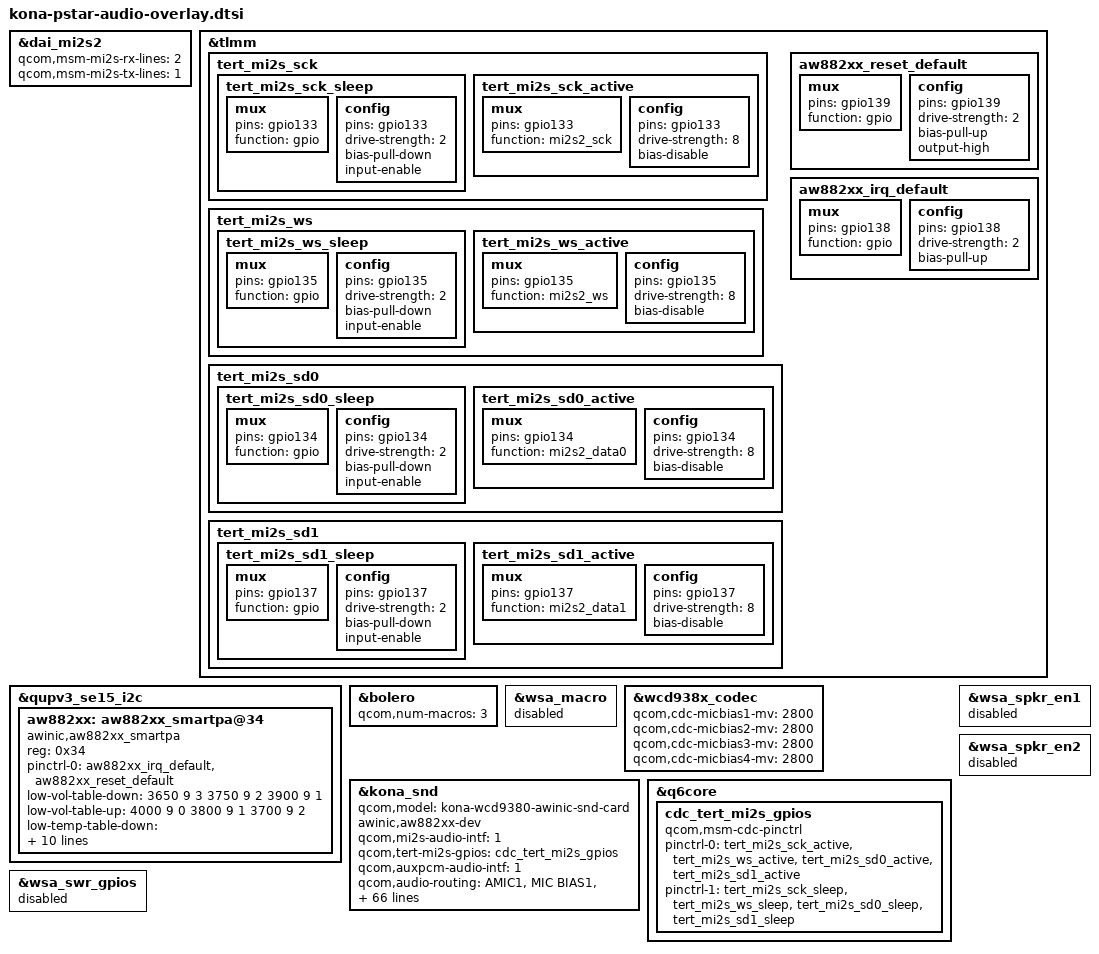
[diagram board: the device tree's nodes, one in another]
#include "kona-audio-overlay.dtsi"

&dai_mi2s2 {
	qcom,msm-mi2s-rx-lines = <2>;
	qcom,msm-mi2s-tx-lines = <1>;
};

&tlmm {

	tert_mi2s_sck {
		tert_mi2s_sck_sleep: tert_mi2s_sck_sleep {
			mux {
				pins = "gpio133";
				function = "gpio";
			};
			config {
				pins = "gpio133";
				drive-strength = <2>; /* 2 mA */
				bias-pull-down; /* PULL DOWN */
				input-enable;
			};
		};

		tert_mi2s_sck_active: tert_mi2s_sck_active {
			mux {
				pins = "gpio133";
				function = "mi2s2_sck";
			};
			config {
				pins = "gpio133";
				drive-strength = <8>; /* 8 mA */
				bias-disable; /* NO PULL */
			};
		};
	};
	tert_mi2s_ws {
		tert_mi2s_ws_sleep: tert_mi2s_ws_sleep {
			mux {
				pins = "gpio135";
				function = "gpio";
			};
			config {
				pins = "gpio135";
				drive-strength = <2>; /* 2 mA */
				bias-pull-down; /* PULL DOWN */
				input-enable;
			};
		};
		tert_mi2s_ws_active: tert_mi2s_ws_active {
			mux {
				pins = "gpio135";
				function = "mi2s2_ws";
			};
			config {
				pins = "gpio135";
				drive-strength = <8>; /* 8 mA */
				bias-disable; /* NO PULL */
			};
		};
	};
	tert_mi2s_sd0 {
		tert_mi2s_sd0_sleep: tert_mi2s_sd0_sleep {
			mux {
				pins = "gpio134";
				function = "gpio";
			};
			config {
				pins = "gpio134";
				drive-strength = <2>; /* 2 mA */
				bias-pull-down; /* PULL DOWN */
				input-enable;
			};
		};
		tert_mi2s_sd0_active: tert_mi2s_sd0_active {
			mux {
				pins = "gpio134";
				function = "mi2s2_data0";
			};
			config {
				pins = "gpio134";
				drive-strength = <8>; /* 8 mA */
				bias-disable; /* NO PULL */
			};
		};
	};
	tert_mi2s_sd1 {
		tert_mi2s_sd1_sleep: tert_mi2s_sd1_sleep {
			mux {
				pins = "gpio137";
				function = "gpio";
			};
			config {
				pins = "gpio137";
				drive-strength = <2>; /* 2 mA */
				bias-pull-down; /* PULL DOWN */
				input-enable;
			};
		};
		tert_mi2s_sd1_active: tert_mi2s_sd1_active {
			mux {
				pins = "gpio137";
				function = "mi2s2_data1";
			};
			config {
				pins = "gpio137";
				drive-strength = <8>; /* 8 mA */
				bias-disable; /* NO PULL */
			};
		};
	};

	aw882xx_reset_default: aw882xx_reset_default {
		mux {
			pins = "gpio139";
			function = "gpio";
		};
		config {
			pins = "gpio139";
			drive-strength = <2>; /* 2 MA */
			bias-pull-up;
			output-high;
		};
	};

	aw882xx_irq_default: aw882xx_irq_default {
		mux {
			pins = "gpio138";
			function = "gpio";
		};
		config {
			pins = "gpio138";
			drive-strength = <2>; /* 2 MA */
			bias-pull-up;
		};
	};
};

&qupv3_se15_i2c {
        status = "ok";

        aw882xx: aw882xx_smartpa@34 {
                compatible = "awinic,aw882xx_smartpa";
                reg = <0x34>;

                pinctrl-names = "default";
                pinctrl-0 = <&aw882xx_irq_default>, <&aw882xx_reset_default>;

                low-vol-table-down = <3650 9 3 3750 9 2 3900 9 1>;
                low-vol-table-up = <4000 9 0 3800 9 1 3700 9 2>;

                low-temp-table-down = <0xFFFFFFFB 0x4 0x10 0xFFBEAE7E 0x0 0x5 0x9 0xFFD80505 0x5 0x6 0x6 0xFFED714D>;
                low-temp-table-up = <0x7 0x9 0x0 0x00000000 0x2 0x6 0x06 0xFFED714D 0xFFFFFFE 0x05 0x09 0xFFD80505>;

                afe-rx-portid = <0x1004>;
                afe-tx-portid = <0x1005>;

                reset-gpio = <&tlmm 139 0>;
                irq-gpio = <&tlmm 138 0x2008>;
                monitor-flag = <1>;
		fade-flag = <1>;
                monitor-timer-val = <3000>;
                status = "okay";
        };
};

&bolero {
	qcom,num-macros = <3>;
};

&wsa_macro {
	status = "disabled";
};

&wcd938x_codec {
	qcom,cdc-micbias1-mv = <2800>;
	qcom,cdc-micbias2-mv = <2800>;
	qcom,cdc-micbias3-mv = <2800>;
	qcom,cdc-micbias4-mv = <2800>;
};

&kona_snd {
        qcom,model = "kona-wcd9380-awinic-snd-card";
	awinic,aw882xx-dev;
        qcom,mi2s-audio-intf = <1>;
	qcom,tert-mi2s-gpios = <&cdc_tert_mi2s_gpios>;
        qcom,auxpcm-audio-intf = <1>;
	qcom,audio-routing =
		"AMIC1", "MIC BIAS1",
		"MIC BIAS1", "Analog Mic1",
		"AMIC2", "MIC BIAS2",
		"MIC BIAS2", "Analog Mic2",
		"AMIC3", "MIC BIAS3",
		"MIC BIAS3", "Analog Mic3",
		"AMIC4", "MIC BIAS4",
		"MIC BIAS4", "Analog Mic4",
		"AMIC5", "MIC BIAS4",
		"MIC BIAS4", "Analog Mic5",
		"TX DMIC0", "MIC BIAS3",
		"MIC BIAS3", "Digital Mic0",
		"TX DMIC1", "MIC BIAS3",
		"MIC BIAS3", "Digital Mic1",
		"TX DMIC2", "MIC BIAS1",
		"MIC BIAS1", "Digital Mic2",
		"TX DMIC3", "MIC BIAS1",
		"MIC BIAS1", "Digital Mic3",
		"TX DMIC4", "MIC BIAS4",
		"MIC BIAS4", "Digital Mic4",
		"TX DMIC5", "MIC BIAS4",
		"MIC BIAS4", "Digital Mic5",
		"IN1_HPHL", "HPHL_OUT",
		"IN2_HPHR", "HPHR_OUT",
		"IN3_AUX", "AUX_OUT",
		"TX SWR_ADC0", "ADC1_OUTPUT",
		"TX SWR_ADC1", "ADC2_OUTPUT",
		"TX SWR_ADC2", "ADC3_OUTPUT",
		"TX SWR_ADC3", "ADC4_OUTPUT",
		"TX SWR_DMIC0", "DMIC1_OUTPUT",
		"TX SWR_DMIC1", "DMIC2_OUTPUT",
		"TX SWR_DMIC2", "DMIC3_OUTPUT",
		"TX SWR_DMIC3", "DMIC4_OUTPUT",
		"TX SWR_DMIC4", "DMIC5_OUTPUT",
		"TX SWR_DMIC5", "DMIC6_OUTPUT",
		"TX SWR_DMIC6", "DMIC7_OUTPUT",
		"TX SWR_DMIC7", "DMIC8_OUTPUT",
		"WSA SRC0_INP", "SRC0",
		"WSA_TX DEC0_INP", "TX DEC0 MUX",
		"WSA_TX DEC1_INP", "TX DEC1 MUX",
		"RX_TX DEC0_INP", "TX DEC0 MUX",
		"RX_TX DEC1_INP", "TX DEC1 MUX",
		"RX_TX DEC2_INP", "TX DEC2 MUX",
		"RX_TX DEC3_INP", "TX DEC3 MUX",
		"SpkrRight IN", "WSA_SPK2 OUT",
		"VA_AIF1 CAP", "VA_SWR_CLK",
		"VA_AIF2 CAP", "VA_SWR_CLK",
		"VA_AIF3 CAP", "VA_SWR_CLK",
		"VA MIC BIAS3", "Digital Mic0",
		"VA MIC BIAS3", "Digital Mic1",
		"VA MIC BIAS1", "Digital Mic2",
		"VA MIC BIAS1", "Digital Mic3",
		"VA MIC BIAS4", "Digital Mic4",
		"VA MIC BIAS4", "Digital Mic5",
		"VA DMIC0", "VA MIC BIAS3",
		"VA DMIC1", "VA MIC BIAS3",
		"VA DMIC2", "VA MIC BIAS1",
		"VA DMIC3", "VA MIC BIAS1",
		"VA DMIC4", "VA MIC BIAS4",
		"VA DMIC5", "VA MIC BIAS4",
		"VA SWR_ADC0", "VA_SWR_CLK",
		"VA SWR_ADC1", "VA_SWR_CLK",
		"VA SWR_ADC2", "VA_SWR_CLK",
		"VA SWR_ADC3", "VA_SWR_CLK",
		"VA SWR_MIC0", "VA_SWR_CLK",
		"VA SWR_MIC1", "VA_SWR_CLK",
		"VA SWR_MIC2", "VA_SWR_CLK",
		"VA SWR_MIC3", "VA_SWR_CLK",
		"VA SWR_MIC4", "VA_SWR_CLK",
		"VA SWR_MIC5", "VA_SWR_CLK",
		"VA SWR_MIC6", "VA_SWR_CLK",
		"VA SWR_MIC7", "VA_SWR_CLK",
		"VA SWR_ADC0", "ADC1_OUTPUT",
		"VA SWR_ADC1", "ADC2_OUTPUT",
		"VA SWR_ADC2", "ADC3_OUTPUT",
		"VA SWR_ADC3", "ADC4_OUTPUT",
		"VA SWR_MIC0", "DMIC1_OUTPUT",
		"VA SWR_MIC1", "DMIC2_OUTPUT",
		"VA SWR_MIC2", "DMIC3_OUTPUT",
		"VA SWR_MIC3", "DMIC4_OUTPUT",
		"VA SWR_MIC4", "DMIC5_OUTPUT",
		"VA SWR_MIC5", "DMIC6_OUTPUT",
		"VA SWR_MIC6", "DMIC7_OUTPUT",
		"VA SWR_MIC7", "DMIC8_OUTPUT";
	qcom,msm-mbhc-usbc-audio-supported = <1>;
	qcom,msm-mbhc-hphl-swh = <0>;
	qcom,msm-mbhc-gnd-swh = <0>;
	asoc-codec  = <&stub_codec>, <&bolero>, <&aw882xx>, <&ext_disp_audio_codec>;
	asoc-codec-names = "msm-stub-codec.1", "bolero_codec","aw882xx_codec",
			   "msm-ext-disp-audio-codec-rx";
	qcom,wsa-max-devs = <0>;
	/delete-property/ qcom,wsa-devs;

	qcom,msm-mbhc-hs-mic-max-threshold-mv = <2700>;
	qcom,msm-mbhc-hs-mic-min-threshold-mv = <116>;
	fsa4480-i2c-handle = <&fsa4480>;
};

&q6core {
	cdc_tert_mi2s_gpios: cdc_tert_mi2s_gpios {
		compatible = "qcom,msm-cdc-pinctrl";
		pinctrl-names = "aud_active", "aud_sleep";
		pinctrl-0 = <&tert_mi2s_sck_active &tert_mi2s_ws_active
			&tert_mi2s_sd0_active &tert_mi2s_sd1_active>;
		pinctrl-1 = <&tert_mi2s_sck_sleep &tert_mi2s_ws_sleep
			&tert_mi2s_sd0_sleep &tert_mi2s_sd1_sleep>;
	};
};

&wsa_swr_gpios {
	status = "disabled";
};

&wsa_spkr_en1 {
	status = "disabled";
};

&wsa_spkr_en2 {
	status = "disabled";
};
